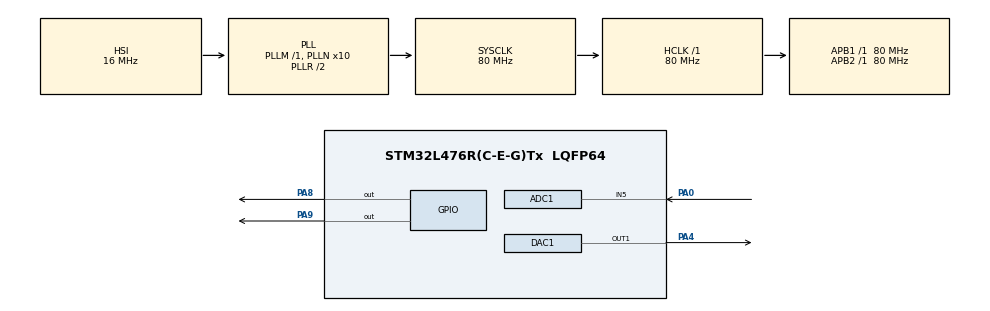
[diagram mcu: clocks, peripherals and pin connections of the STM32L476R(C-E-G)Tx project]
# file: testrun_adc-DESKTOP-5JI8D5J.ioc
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ADC1.Channel-2\#ChannelRegularConversion=ADC_CHANNEL_5
ADC1.ClockPrescaler=ADC_CLOCK_ASYNC_DIV1
ADC1.ContinuousConvMode=DISABLE
ADC1.DMAContinuousRequests=ENABLE
ADC1.EnableRegularConversion=ENABLE
ADC1.ExternalTrigConv=ADC_EXTERNALTRIG_T6_TRGO
ADC1.ExternalTrigConvEdge=ADC_EXTERNALTRIGCONVEDGE_FALLING
ADC1.NbrOfConversionFlag=1
ADC1.OffsetNumber-2\#ChannelRegularConversion=ADC_OFFSET_NONE
ADC1.OversamplingMode=DISABLE
ADC1.Rank-2\#ChannelRegularConversion=1
ADC1.Resolution=ADC_RESOLUTION_12B
ADC1.SamplingTime-2\#ChannelRegularConversion=ADC_SAMPLETIME_2CYCLES_5
ADC1.master=1
DAC1.DAC_OutputBuffer-DAC_OUT1=DAC_OUTPUTBUFFER_ENABLE
DAC1.DAC_Trigger-DAC_OUT1=DAC_TRIGGER_T7_TRGO
Dma.ADC1.1.Direction=DMA_PERIPH_TO_MEMORY
Dma.ADC1.1.Instance=DMA1_Channel1
Dma.ADC1.1.MemDataAlignment=DMA_MDATAALIGN_WORD
Dma.ADC1.1.MemInc=DMA_MINC_ENABLE
Dma.ADC1.1.Mode=DMA_CIRCULAR
Dma.ADC1.1.PeriphDataAlignment=DMA_PDATAALIGN_WORD
Dma.ADC1.1.PeriphInc=DMA_PINC_DISABLE
Dma.ADC1.1.Priority=DMA_PRIORITY_HIGH
Dma.DAC_CH1.0.Direction=DMA_MEMORY_TO_PERIPH
Dma.DAC_CH1.0.Instance=DMA1_Channel3
Dma.DAC_CH1.0.MemDataAlignment=DMA_MDATAALIGN_WORD
Dma.DAC_CH1.0.MemInc=DMA_MINC_ENABLE
Dma.DAC_CH1.0.Mode=DMA_CIRCULAR
Dma.DAC_CH1.0.PeriphDataAlignment=DMA_PDATAALIGN_WORD
Dma.DAC_CH1.0.PeriphInc=DMA_PINC_DISABLE
Dma.DAC_CH1.0.Priority=DMA_PRIORITY_HIGH
Dma.Request0=DAC_CH1
Dma.Request1=ADC1
Mcu.Family=STM32L4
Mcu.Name=STM32L476R(C-E-G)Tx
Mcu.Package=LQFP64
NVIC.DMA1_Channel1_IRQn=true\:0\:0\:false\:false\:true\:false\:true
NVIC.DMA1_Channel3_IRQn=true\:0\:0\:false\:false\:true\:false\:true
NVIC.PriorityGroup=NVIC_PRIORITYGROUP_4
NVIC.TIM6_DAC_IRQn=true\:0\:0\:false\:false\:true\:true\:true
PA0.Signal=ADCx_IN5
PA4.Signal=COMP_DAC11_group
PA8.Signal=GPIO_Output
PA9.Signal=GPIO_Output
ProjectManager.HeapSize=0x200
ProjectManager.StackSize=0x400
ProjectManager.TargetToolchain=STM32CubeIDE
RCC.ADCCLockSelection=RCC_ADCCLKSOURCE_SYSCLK
RCC.ADCFreq_Value=80000000
RCC.AHBFreq_Value=80000000
RCC.APB1Freq_Value=80000000
RCC.APB1TimFreq_Value=80000000
RCC.APB2Freq_Value=80000000
RCC.APB2TimFreq_Value=80000000
RCC.CortexFreq_Value=80000000
RCC.HCLKFreq_Value=80000000
RCC.HSE_VALUE=8000000
RCC.HSI_VALUE=16000000
RCC.LSE_VALUE=32768
RCC.MSI_VALUE=4000000
RCC.PLLN=10
RCC.PLLSourceVirtual=RCC_PLLSOURCE_HSI
RCC.PREFETCH_ENABLE=1
RCC.SYSCLKFreq_VALUE=80000000
RCC.SYSCLKSource=RCC_SYSCLKSOURCE_PLLCLK
RCC.USBFreq_Value=64000000
RCC.VCOOutputFreq_Value=160000000
SH.ADCx_IN5.0=ADC1_IN5,IN5-Single-Ended
SH.COMP_DAC11_group.0=DAC1_OUT1,DAC_OUT1
TIM6.AutoReloadPreload=TIM_AUTORELOAD_PRELOAD_DISABLE
TIM6.Period=1666
TIM6.Prescaler=0
TIM6.TIM_MasterOutputTrigger=TIM_TRGO_UPDATE
TIM7.Period=1666
TIM7.TIM_MasterOutputTrigger=TIM_TRGO_UPDATE
VP_TIM6_VS_ClockSourceINT.Mode=Enable_Timer
VP_TIM7_VS_ClockSourceINT.Mode=Enable_Timer
board=NUCLEO-L476RG

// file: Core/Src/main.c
/* USER CODE BEGIN Header */
/**
  ******************************************************************************
  * @file           : main.c
  * @brief          : Main program body
  ******************************************************************************
  * @attention
  *
  * <h2><center>&copy; Copyright (c) 2021 STMicroelectronics.
  * All rights reserved.</center></h2>
  *
  * This software component is licensed by ST under BSD 3-Clause license,
  * the "License"; You may not use this file except in compliance with the
  * License. You may obtain a copy of the License at:
  *                        opensource.org/licenses/BSD-3-Clause
  *
  ******************************************************************************
  */
/* USER CODE END Header */
#include "main.h"

/* USER CODE BEGIN Includes */
#include <string.h>
/* USER CODE END Includes */

ADC_HandleTypeDef hadc1;
DMA_HandleTypeDef hdma_adc1;

DAC_HandleTypeDef hdac1;
DMA_HandleTypeDef hdma_dac_ch1;

TIM_HandleTypeDef htim6;
TIM_HandleTypeDef htim7;

/* USER CODE BEGIN PV */

// copy new handles to mymain.h
#include "mymain.h"

/* USER CODE END PV */

void SystemClock_Config(void);
static void MX_GPIO_Init(void);
static void MX_DMA_Init(void);
static void MX_DAC1_Init(void);
static void MX_ADC1_Init(void);
static void MX_TIM6_Init(void);
static void MX_TIM7_Init(void);

int main(void)
{

  /* MCU Configuration--------------------------------------------------------*/

  /* Reset of all peripherals, Initializes the Flash interface and the Systick. */
  HAL_Init();

  /* Configure the system clock */
  SystemClock_Config();

  /* Initialize all configured peripherals */
  MX_GPIO_Init();
  MX_DMA_Init();
  MX_DAC1_Init();
  MX_ADC1_Init();
  MX_TIM6_Init();
  MX_TIM7_Init();
  /* USER CODE BEGIN 2 */

  mymain();
  /* USER CODE END 2 */

  /* Infinite loop */
  /* USER CODE BEGIN WHILE */
  while (0)
  {
    /* USER CODE END WHILE */

  }
}

void SystemClock_Config(void)
{
  RCC_OscInitTypeDef RCC_OscInitStruct = {0};
  RCC_ClkInitTypeDef RCC_ClkInitStruct = {0};

  /** Configure the main internal regulator output voltage
  */
  if (HAL_PWREx_ControlVoltageScaling(PWR_REGULATOR_VOLTAGE_SCALE1) != HAL_OK)
  {
    Error_Handler();
  }
  /** Initializes the RCC Oscillators according to the specified parameters
  * in the RCC_OscInitTypeDef structure.
  */
  RCC_OscInitStruct.OscillatorType = RCC_OSCILLATORTYPE_HSI;
  RCC_OscInitStruct.HSIState = RCC_HSI_ON;
  RCC_OscInitStruct.HSICalibrationValue = RCC_HSICALIBRATION_DEFAULT;
  RCC_OscInitStruct.PLL.PLLState = RCC_PLL_ON;
  RCC_OscInitStruct.PLL.PLLSource = RCC_PLLSOURCE_HSI;
  RCC_OscInitStruct.PLL.PLLM = 1;
  RCC_OscInitStruct.PLL.PLLN = 10;
  RCC_OscInitStruct.PLL.PLLP = RCC_PLLP_DIV7;
  RCC_OscInitStruct.PLL.PLLQ = RCC_PLLQ_DIV2;
  RCC_OscInitStruct.PLL.PLLR = RCC_PLLR_DIV2;
  if (HAL_RCC_OscConfig(&RCC_OscInitStruct) != HAL_OK)
  {
    Error_Handler();
  }
  /** Initializes the CPU, AHB and APB buses clocks
  */
  RCC_ClkInitStruct.ClockType = RCC_CLOCKTYPE_HCLK|RCC_CLOCKTYPE_SYSCLK
                              |RCC_CLOCKTYPE_PCLK1|RCC_CLOCKTYPE_PCLK2;
  RCC_ClkInitStruct.SYSCLKSource = RCC_SYSCLKSOURCE_PLLCLK;
  RCC_ClkInitStruct.AHBCLKDivider = RCC_SYSCLK_DIV1;
  RCC_ClkInitStruct.APB1CLKDivider = RCC_HCLK_DIV1;
  RCC_ClkInitStruct.APB2CLKDivider = RCC_HCLK_DIV1;

  if (HAL_RCC_ClockConfig(&RCC_ClkInitStruct, FLASH_LATENCY_4) != HAL_OK)
  {
    Error_Handler();
  }
}

static void MX_ADC1_Init(void)
{

  ADC_MultiModeTypeDef multimode = {0};
  ADC_ChannelConfTypeDef sConfig = {0};

  /** Common config
  */
  hadc1.Instance = ADC1;
  hadc1.Init.ClockPrescaler = ADC_CLOCK_ASYNC_DIV1;
  hadc1.Init.Resolution = ADC_RESOLUTION_12B;
  hadc1.Init.DataAlign = ADC_DATAALIGN_RIGHT;
  hadc1.Init.ScanConvMode = ADC_SCAN_DISABLE;
  hadc1.Init.EOCSelection = ADC_EOC_SINGLE_CONV;
  hadc1.Init.LowPowerAutoWait = DISABLE;
  hadc1.Init.ContinuousConvMode = DISABLE;
  hadc1.Init.NbrOfConversion = 1;
  hadc1.Init.DiscontinuousConvMode = DISABLE;
  hadc1.Init.ExternalTrigConv = ADC_EXTERNALTRIG_T6_TRGO;
  hadc1.Init.ExternalTrigConvEdge = ADC_EXTERNALTRIGCONVEDGE_FALLING;
  hadc1.Init.DMAContinuousRequests = ENABLE;
  hadc1.Init.Overrun = ADC_OVR_DATA_PRESERVED;
  hadc1.Init.OversamplingMode = DISABLE;
  if (HAL_ADC_Init(&hadc1) != HAL_OK)
  {
    Error_Handler();
  }
  /** Configure the ADC multi-mode
  */
  multimode.Mode = ADC_MODE_INDEPENDENT;
  if (HAL_ADCEx_MultiModeConfigChannel(&hadc1, &multimode) != HAL_OK)
  {
    Error_Handler();
  }
  /** Configure Regular Channel
  */
  sConfig.Channel = ADC_CHANNEL_5;
  sConfig.Rank = ADC_REGULAR_RANK_1;
  sConfig.SamplingTime = ADC_SAMPLETIME_2CYCLES_5;
  sConfig.SingleDiff = ADC_SINGLE_ENDED;
  sConfig.OffsetNumber = ADC_OFFSET_NONE;
  sConfig.Offset = 0;
  if (HAL_ADC_ConfigChannel(&hadc1, &sConfig) != HAL_OK)
  {
    Error_Handler();
  }

}

static void MX_DAC1_Init(void)
{

  DAC_ChannelConfTypeDef sConfig = {0};

  /** DAC Initialization
  */
  hdac1.Instance = DAC1;
  if (HAL_DAC_Init(&hdac1) != HAL_OK)
  {
    Error_Handler();
  }
  /** DAC channel OUT1 config
  */
  sConfig.DAC_SampleAndHold = DAC_SAMPLEANDHOLD_DISABLE;
  sConfig.DAC_Trigger = DAC_TRIGGER_T7_TRGO;
  sConfig.DAC_OutputBuffer = DAC_OUTPUTBUFFER_ENABLE;
  sConfig.DAC_ConnectOnChipPeripheral = DAC_CHIPCONNECT_DISABLE;
  sConfig.DAC_UserTrimming = DAC_TRIMMING_FACTORY;
  if (HAL_DAC_ConfigChannel(&hdac1, &sConfig, DAC_CHANNEL_1) != HAL_OK)
  {
    Error_Handler();
  }

}

static void MX_TIM6_Init(void)
{

  TIM_MasterConfigTypeDef sMasterConfig = {0};

  htim6.Instance = TIM6;
  htim6.Init.Prescaler = 0;
  htim6.Init.CounterMode = TIM_COUNTERMODE_UP;
  htim6.Init.Period = 1000;
  htim6.Init.AutoReloadPreload = TIM_AUTORELOAD_PRELOAD_DISABLE;
  if (HAL_TIM_Base_Init(&htim6) != HAL_OK)
  {
    Error_Handler();
  }
  sMasterConfig.MasterOutputTrigger = TIM_TRGO_UPDATE;
  sMasterConfig.MasterSlaveMode = TIM_MASTERSLAVEMODE_DISABLE;
  if (HAL_TIMEx_MasterConfigSynchronization(&htim6, &sMasterConfig) != HAL_OK)
  {
    Error_Handler();
  }

}

static void MX_TIM7_Init(void)
{

  TIM_MasterConfigTypeDef sMasterConfig = {0};

  htim7.Instance = TIM7;
  htim7.Init.Prescaler = 0;
  htim7.Init.CounterMode = TIM_COUNTERMODE_UP;
  htim7.Init.Period = 1000;
  htim7.Init.AutoReloadPreload = TIM_AUTORELOAD_PRELOAD_DISABLE;
  if (HAL_TIM_Base_Init(&htim7) != HAL_OK)
  {
    Error_Handler();
  }
  sMasterConfig.MasterOutputTrigger = TIM_TRGO_UPDATE;
  sMasterConfig.MasterSlaveMode = TIM_MASTERSLAVEMODE_DISABLE;
  if (HAL_TIMEx_MasterConfigSynchronization(&htim7, &sMasterConfig) != HAL_OK)
  {
    Error_Handler();
  }

}

static void MX_DMA_Init(void)
{

  /* DMA controller clock enable */
  __HAL_RCC_DMA1_CLK_ENABLE();

  /* DMA interrupt init */
  /* DMA1_Channel1_IRQn interrupt configuration */
  HAL_NVIC_SetPriority(DMA1_Channel1_IRQn, 0, 0);
  HAL_NVIC_EnableIRQ(DMA1_Channel1_IRQn);
  /* DMA1_Channel3_IRQn interrupt configuration */
  HAL_NVIC_SetPriority(DMA1_Channel3_IRQn, 0, 0);
  HAL_NVIC_EnableIRQ(DMA1_Channel3_IRQn);

}

static void MX_GPIO_Init(void)
{
  GPIO_InitTypeDef GPIO_InitStruct = {0};

  /* GPIO Ports Clock Enable */
  __HAL_RCC_GPIOA_CLK_ENABLE();

  /*Configure GPIO pin Output Level */
  HAL_GPIO_WritePin(GPIOA, GPIO_PIN_8|GPIO_PIN_9, GPIO_PIN_RESET);

  /*Configure GPIO pins : PA8 PA9 */
  GPIO_InitStruct.Pin = GPIO_PIN_8|GPIO_PIN_9;
  GPIO_InitStruct.Mode = GPIO_MODE_OUTPUT_PP;
  GPIO_InitStruct.Pull = GPIO_NOPULL;
  GPIO_InitStruct.Speed = GPIO_SPEED_FREQ_LOW;
  HAL_GPIO_Init(GPIOA, &GPIO_InitStruct);

}

void Error_Handler(void)
{
  __disable_irq();
  while (1)
  {
  }
}

/************************ (C) COPYRIGHT STMicroelectronics *****END OF FILE****/
